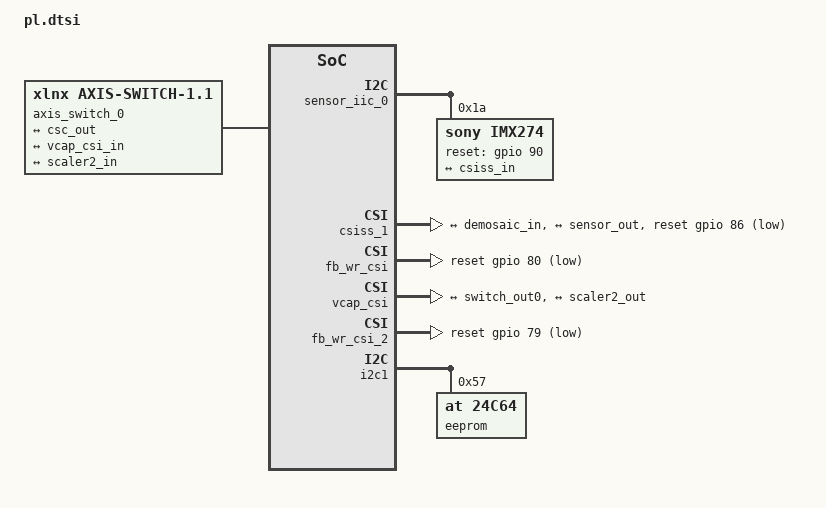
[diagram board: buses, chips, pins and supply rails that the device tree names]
/*
 * CAUTION: This file is automatically generated by Xilinx.
 * Version:  
 * Today is: Tue Jul 24 03:37:50 2018
 */


/ {
	amba_pl: amba_pl@0 {
		#address-cells = <2>;
		#size-cells = <2>;
		compatible = "simple-bus";
		ranges ;
	vcu_0: vcu@b0100000 {
		#address-cells = <2>;
		#size-cells = <2>;
		#clock-cells= <1>;
		clock-names = "pll_ref", "aclk", "vcu_core_enc", "vcu_core_dec", "vcu_mcu_enc", "vcu_mcu_dec";
		clocks = <&misc_clk_0>, <&misc_clk_2>, <&vcu_0 1>, <&vcu_0 2>, <&vcu_0 3>, <&vcu_0 4>;
		compatible = "xlnx,vcu-1.1", "xlnx,vcu";
		interrupt-names = "vcu_host_interrupt";
		interrupt-parent = <&gic>;
		interrupts = <0 107 4>;
		ranges ;
		reg = <0x0 0xb0140000 0x0 0x1000>,
			<0x0 0xb0141000 0x0 0x1000>;
		reg-names = "vcu_slcr", "logicore";
		encoder: al5e@b0100000 {
			compatible = "al,al5e-1.1", "al,al5e";
			interrupt-parent = <&gic>;
			interrupts = <0 107 4>;
			reg = <0x0 0xb0100000 0x0 0x10000>;
		};
			 /*
		decoder: al5d@a0120000 {
			compatible = "al,al5d-1.1", "al,al5d";
			interrupt-parent = <&gic>;
			interrupts = <0 93 4>;
			reg = <0x0 0xa0120000 0x0 0x10000>;
		}; */
	};
        vid_stream_clk: vid_stream_clk {
                compatible = "fixed-clock";
                #clock-cells = <0>;
                clock-frequency = <300000000>;
        };

        vid_s_axi_clk: vid_s_axi_clk {
                compatible = "fixed-clock";
                #clock-cells = <0>;
                clock-frequency = <99990000>;
        };

	misc_clk_0: misc_clk_0 {
			#clock-cells = <0>;
			clock-frequency = <33333333>;
			compatible = "fixed-clock";
	};

	misc_clk_2: misc_clk_2 {
			#clock-cells = <0>;
			clock-frequency = <100000000>;
			compatible = "fixed-clock";
	};


	/* csi-rx */
	sensor_iic_0: i2c@b0010000 {
		#address-cells = <1>;
		#size-cells = <0>;
		status = "okay";
		compatible = "xlnx,xps-iic-2.00.a";
		interrupt-parent = <&gic>;
		interrupts = <0 104 4>;
		reg = <0x0 0xb0010000 0x0 0x1000>;
		clocks = <&vid_s_axi_clk>;
	};

	csiss_1: csiss@b0000000 {
		compatible = "xlnx,mipi-csi2-rx-subsystem-2.0";
		reg = <0x0 0xb0000000 0x0 0x10000>;
		clocks = <&vid_stream_clk>;
		interrupt-parent = <&gic>;
		interrupts = <0 106 4>;

		xlnx,max-lanes = <0x4>;
		xlnx,en-active-lanes;
		xlnx,vc = <0x4>;
		xlnx,csi-pxl-format = "RAW8";
		xlnx,vfb;
		xlnx,ppc = <0x4>;
		xlnx,axis-tdata-width = <0x20>;
		reset-gpios = <&gpio 86 1>;

		ports {
			#address-cells = <1>;
			#size-cells = <0>;

			port@0 {
				reg = <0>;

				xlnx,video-format = <12>;
				xlnx,video-width = <8>;
				xlnx,cfa-pattern = "rggb";

				csiss_out: endpoint {
					remote-endpoint = <&demosaic_in>;
				};
			};
			port@1 {
				reg = <1>;

				xlnx,video-format = <12>;
				xlnx,video-width = <8>;
				xlnx,cfa-pattern = "rggb";

				csiss_in: endpoint {
					data-lanes = <1 2 3 4>;
					remote-endpoint = <&sensor_out>;
				};
			};
		};
	};

	v_demosaic_0: v_demosaic@A2010000{
		compatible = "xlnx,v-demosaic";
		reg = <0x0 0xA2010000 0x0 0x10000>;
		clocks = <&vid_stream_clk>;
		xlnx,max-width = <3840>;
		xlnx,max-height = <2160>;

		reset-gpios = <&gpio 82 1>;

		ports {
			#address-cells = <1>;
			#size-cells = <0>;

			port@0 {
				reg = <0>;

				xlnx,video-width = <8>;
				xlnx,cfa-pattern = "rggb";

				demosaic_in: endpoint {
					remote-endpoint = <&csiss_out>;
				};
			};

			port@1 {
				reg = <1>;

				xlnx,video-width = <8>;

				demosaic_out: endpoint {
					remote-endpoint = <&gamma_in>;
				};
			};
		};
	};

	gamma_1: v_gamma@A2080000{
		compatible = "xlnx,v-gamma-lut";
		reg = <0x0 0xA2080000 0x0 0x10000>;
		clocks = <&vid_stream_clk>;
		xlnx,max-height = <2160>;
		xlnx,max-width = <3840>;

		reset-gpios = <&gpio 85 1>;

		ports {
			#address-cells = <1>;
			#size-cells = <0>;

			port@0 {
				reg = <0>;

				xlnx,video-width = <8>;

				gamma_in: endpoint {
					remote-endpoint = <&demosaic_out>;
				};
			};

			port@1 {
				reg = <1>;

				xlnx,video-width = <8>;

				gamma_out: endpoint {
					remote-endpoint = <&csc_in>;
				};
			};
		};
	};

	csc_1: csc@a2000000 {
		compatible = "xlnx,v-vpss-csc";
		reg = <0x0 0xa2000000 0x0 0x10000>;
		clocks = <&vid_stream_clk>;
		xlnx,max-width = <3840>;
		xlnx,max-height = <2160>;

		reset-gpios = <&gpio 84 1>;

		ports {
			#address-cells = <1>;
			#size-cells = <0>;

			port@0 {
				reg = <0>;

				xlnx,video-format = <2>;
				xlnx,video-width = <8>;

				csc_in: endpoint {
					remote-endpoint = <&gamma_out>;
				};
			};
			port@1 {
				reg = <1>;

				xlnx,video-format = <2>;
				xlnx,video-width = <8>;

				csc_out: endpoint {
					remote-endpoint = <&switch_in0>;
				};
			};
		};
	};

	fb_wr_csi: fb_wr@a2020000 {
		compatible = "xlnx,axi-frmbuf-wr-v2.1";
		reg = <0x0 0xa2020000 0x0 0x10000>;
		#dma-cells = <1>;
		interrupt-parent = <&gic>;
		interrupts = <0 105 4>;
		clocks = <&vid_stream_clk>;
		clock-names = "ap_clk";
		xlnx,vid-formats = "yuyv", "nv12", "y8", "uyvy", "rgb888";
		xlnx,pixels-per-clock = <2>;
		xlnx,dma-addr-width = <32>;
                xlnx,max-height = <1080>;
                xlnx,max-width = <1920>;

		reset-gpios = <&gpio 80 1>;
	};

	vcap_csi {
		compatible = "xlnx,video";
		dmas = <&fb_wr_csi 0>, <&fb_wr_csi_2 0>;
		dma-names = "port0", "port1";

		ports {
			#address-cells = <1>;
			#size-cells = <0>;

			port@0 {
				reg = <0>;
				direction = "input";

				vcap_csi_in: endpoint {
					remote-endpoint = <&switch_out0>;
				};
			};

			port@1 {
				reg = <1>;
				direction = "input";

				vcap_csi2_in: endpoint {
					remote-endpoint = <&scaler2_out>;
				};
			};

		};
	};

	axis_switch_0: axis_switch@0 {
	compatible = "xlnx,axis-switch-1.1";
	xlnx,routing-mode = <0x0>;
	xlnx,num-si-slots = <0x1>;
	xlnx,num-mi-slots = <0x2>;
	clocks = <&vid_stream_clk>;
	clock-names = "aclk";

		ports {
			#address-cells = <1>;
			#size-cells = <0>;
			port@0 {
				reg = <0>;
				switch_in0: endpoint {
					remote-endpoint = <&csc_out>;
				};
			};
			port@1 {
				reg = <1>;
				switch_out0: endpoint {
					remote-endpoint = <&vcap_csi_in>;
				};
			};
			port@2 {
				reg = <2>;
				switch_out1: endpoint {
					remote-endpoint = <&scaler2_in>;
				};
			};
		};

	};

	scaler_2: scaler@a2040000 {
		/* compatible = "xlnx,v-vpss-scaler"; */
		compatible = "xlnx,v-vpss-scaler-2.2";
		reg = <0x0 0xa2040000 0x0 0x40000>;
		clocks = <&vid_stream_clk>, <&vid_stream_clk>;
		clock-names = "aclk_axis", "aclk_ctrl";

		xlnx,num-hori-taps = <8>;
		xlnx,num-vert-taps = <8>;
		xlnx,max-num-phases = <64>;
		xlnx,max-lines = <2160>;
		xlnx,max-pixels = <3840>;
		xlnx,pix-per-clk = <2>;

		reset-gpios = <&gpio 81 1>;
		xlnx,max-width = <3840>;
		xlnx,max-height = <2160>;

		ports {
			#address-cells = <1>;
			#size-cells = <0>;

			port@0 {
				reg = <0>;

				xlnx,video-format = <2>;
				xlnx,video-width = <8>;

				scaler2_in: endpoint {
					remote-endpoint = <&switch_out1>;
				};
			};
			port@1 {
				reg = <1>;

				xlnx,video-format = <0>;
				xlnx,video-width = <8>;

				scaler2_out: endpoint {
					remote-endpoint = <&vcap_csi2_in>;
				};
			};
		};
	};

	fb_wr_csi_2: fb_wr@a2030000 {
		compatible = "xlnx,axi-frmbuf-wr-v2.1";
		reg = <0x0 0xa2030000 0x0 0x10000>;
		#dma-cells = <1>;
		interrupt-parent = <&gic>;
		interrupts = <0 108 4>;
		clocks = <&vid_stream_clk>;
		clock-names = "ap_clk";
		xlnx,vid-formats = "yuyv", "nv12", "y8", "uyvy", "rgb888";
		xlnx,pixels-per-clock = <2>;
		xlnx,dma-addr-width = <32>;
                xlnx,max-height = <480>;
                xlnx,max-width = <640>;

		reset-gpios = <&gpio 79 1>;
	};

        v_multi_scaler_1: v_multi_scaler@a20a0000 {
                clock-names = "ap_clk";
                clocks = <&misc_clk_0>;
                compatible = "xlnx,v-multi-scaler-1.0", "xlnx,v-multi-scaler-v1.0";
                interrupt-names = "interrupt";
                interrupt-parent = <&gic>;
                interrupts = <0 109 4>;
                reg = <0x0 0xa20a0000 0x0 0x20000>;
                reset-gpios = <&gpio 83 1>;
		xlnx,dma-addr-width = <0x20>;
		xlnx,pixels-per-clock = /bits/ 8 <2>;
                xlnx,max-chan = <1>;
                xlnx,max-height = <480>;
                xlnx,max-width = <640>;
                xlnx,num-taps = <6>;
                xlnx,vid-formats = "nv12", "rgb888";
        };

	};

		
};
&sata {
	ceva,p0-burst-params = /bits/ 8 <0x13 0x08 0x4A 0x06>;
	ceva,p0-cominit-params = /bits/ 8 <0x18 0x40 0x18 0x28>;
	ceva,p0-comwake-params = /bits/ 8 <0x06 0x14 0x08 0x0E>;
	ceva,p0-retry-params = /bits/ 16 <0x96A4 0x3FFC>;
	ceva,p1-burst-params = /bits/ 8 <0x13 0x08 0x4A 0x06>;
	ceva,p1-cominit-params = /bits/ 8 <0x18 0x40 0x18 0x28>;
	ceva,p1-comwake-params = /bits/ 8 <0x06 0x14 0x08 0x0E>;
	ceva,p1-retry-params = /bits/ 16 <0x96A4 0x3FFC>;
};

&i2c1 {
	i2cswitch@75 {
		i2c@0 {
			eeprom@57 { /* HPC0_IIC */
				compatible = "at,24c64";
				reg = <0x57>;
			};
		};
	};
};

&sensor_iic_0 {
	imx274: sensor@1a{
		compatible = "sony,imx274";
		reg = <0x1a>;
		#address-cells = <1>;
		#size-cells = <0>;
		reset-gpios = <&gpio 90 0>;

		port@0 {
			reg = <0>;

			sensor_out: endpoint {
				remote-endpoint = <&csiss_in>;
			};
		};
	};
};
